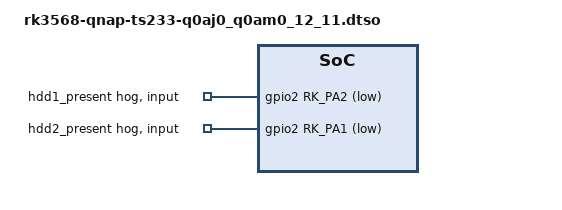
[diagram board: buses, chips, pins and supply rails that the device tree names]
// SPDX-License-Identifier: (GPL-2.0-or-later OR MIT)
/*
 * Device tree overlay for the WolfVision PF5 Visualizer display.
 *
 * Copyright (C) 2024 WolfVision GmbH.
 */

/dts-v1/;
/plugin/;

#include <dt-bindings/gpio/gpio.h>
#include <dt-bindings/pinctrl/rockchip.h>

&gpio2 {
	hdd1-present-hog {
		gpios = <RK_PA2 GPIO_ACTIVE_LOW>;
		gpio-hog;
		input;
		line-name = "hdd1_present";
	};

	hdd2-present-hog {
		gpios = <RK_PA1 GPIO_ACTIVE_LOW>;
		gpio-hog;
		input;
		line-name = "hdd2_present";
	};
};

&pinctrl {
	pinctrl-names = "default";
	pinctrl-0 = <&hdd1_present_pin &hdd2_present_pin>;

	hdd-present {
		hdd1_present_pin: hdd1-present-pin {
			rockchip,pins = <2 RK_PA2 RK_FUNC_GPIO &pcfg_pull_up>;
		};

		hdd2_present_pin: hdd2-present-pin {
			rockchip,pins = <2 RK_PA1 RK_FUNC_GPIO &pcfg_pull_up>;
		};
	};
};
